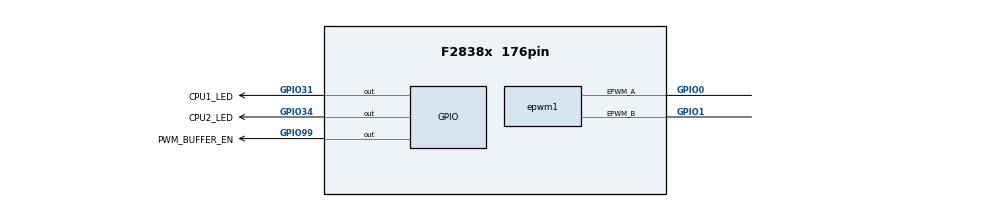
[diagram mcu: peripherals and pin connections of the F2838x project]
/**
 * @cliArgs --device "F2838x" --part "F2838x_176pin" --package "176pin" --context "CPU1" --product "C2000WARE@6.00.01.00"
 * @versions {"tool":"1.27.1+4634"}
 */

/**
 * Import the modules used in this configuration.
 */
const gpio  = scripting.addModule("/driverlib/gpio.js", {}, false);
const gpio1 = gpio.addInstance();
const gpio2 = gpio.addInstance();
const gpio3 = gpio.addInstance();
const device_support = scripting.addModule("/driverlib/device_support.js");
const ipc   = scripting.addModule("/driverlib/ipc.js");
const epwm  = scripting.addModule("/driverlib/epwm.js", {}, false);
const epwm1 = epwm.addInstance();

/**
 * Write custom configuration values to the imported modules.
 */
gpio1.direction       = "GPIO_DIR_MODE_OUT";
gpio1.$name           = "CPU1_LED";
gpio1.gpioPin.$assign = "GPIO31";

gpio2.direction       = "GPIO_DIR_MODE_OUT";
gpio2.controllerCore  = "GPIO_CORE_CPU2";
gpio2.$name           = "CPU2_LED";
gpio2.gpioPin.$assign = "GPIO34";

gpio3.direction         = "GPIO_DIR_MODE_OUT";
gpio3.writeInitialValue = true;
gpio3.initialValue      = 0;
gpio3.$name             = "PWM_BUFFER_EN";
gpio3.gpioPin.$assign   = "GPIO99";

ipc.ipcRegisterFlag = ["IPC_FLAG31"];
ipc.flagHandler31   = "IPC_SYNC";

epwm1.$name                                                    = "myEPWM1";
epwm1.epwm.$assign                                             = "EPWM1";
epwm1.epwm.epwm_aPin.$assign                                   = "GPIO0";
epwm1.epwm.epwm_bPin.$assign                                   = "GPIO1";
epwm1.epwmTimebase_counterMode                                 = "EPWM_COUNTER_MODE_UP";
epwm1.epwmTimebase_period                                      = 1999;
epwm1.epwmCounterCompare_cmpA                                  = 1000;
epwm1.epwmTimebase_clockDiv                                    = "EPWM_CLOCK_DIVIDER_1";
epwm1.epwmTimebase_hsClockDiv                                  = "EPWM_HSCLOCK_DIVIDER_1";
epwm1.epwmActionQualifier_EPWM_AQ_OUTPUT_A_ON_TIMEBASE_ZERO    = "EPWM_AQ_OUTPUT_HIGH";
epwm1.epwmActionQualifier_EPWM_AQ_OUTPUT_A_ON_TIMEBASE_UP_CMPA = "EPWM_AQ_OUTPUT_LOW";

system.clockTree.EPWMCLKDIV.divideValue = 1;
